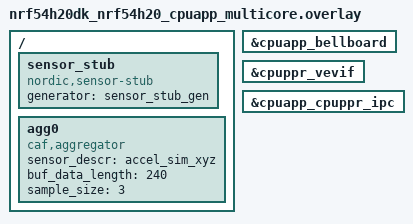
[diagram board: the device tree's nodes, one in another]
/*
 * Copyright (c) 2024 Nordic Semiconductor ASA
 *
 * SPDX-License-Identifier: LicenseRef-Nordic-5-Clause
 */

 /* Replace default ipc0 instance */
/delete-node/ &ipc0;

/ {
	sensor_stub: sensor_stub {
		compatible = "nordic,sensor-stub";
		generator = "sensor_stub_gen";
		status = "okay";
	};

	agg0: agg0 {
		compatible = "caf,aggregator";
		sensor_descr = "accel_sim_xyz";
		buf_data_length = <240>;
		sample_size = <3>;
	};
};

/* Enabled nodes required by IPC
 * Two mboxes, one for each sides and one ipc instance
 */

&cpuapp_bellboard {
	status = "okay";
};

&cpuppr_vevif {
       status = "okay";
};

ipc0: &cpuapp_cpuppr_ipc {
	status = "okay";
};

/* UART and RAM3 instance used by PPR should be enabled at build time
 * using nordic-ppr snippet.
 */
